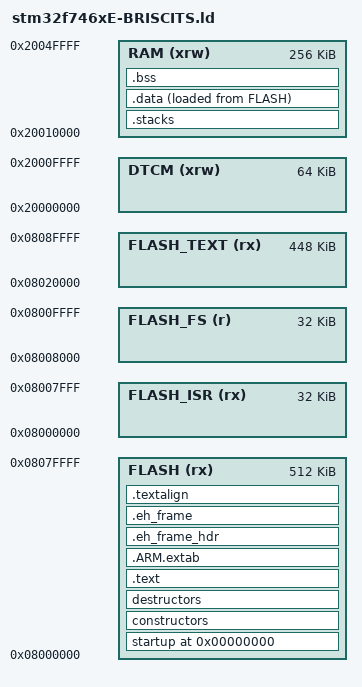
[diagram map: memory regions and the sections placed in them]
/*
    GNU linker script for STM32F746
*/

__main_stack_size__     = 0x0600;
__process_stack_size__  = 0x0600;

/* Specify the memory areas */
MEMORY
{
    FLASH (rx)      : ORIGIN = 0x08000000, LENGTH = 512K
    FLASH_ISR (rx)  : ORIGIN = 0x08000000, LENGTH = 32K     /* sector 0, 32K */
    FLASH_FS (r)    : ORIGIN = 0x08008000, LENGTH = 32K     /* sectors 1 (32K each) */
    FLASH_TEXT (rx) : ORIGIN = 0x08020000, LENGTH = 448K    /* sectors 2-5 2*32Kib 1*128Kib 1*256KiB = 448K */
    DTCM (xrw)      : ORIGIN = 0x20000000, LENGTH = 64K     /* Used for storage cache */
    RAM (xrw)       : ORIGIN = 0x20010000, LENGTH = 256K    /* SRAM1 = 240K, SRAM2 = 16K */
}

__ram_start__           = ORIGIN(RAM);
__ram_size__            = LENGTH(RAM);
__ram_end__             = __ram_start__ + __ram_size__;

SECTIONS
{
    . = 0;
    _text = .;

    startup : ALIGN(16) SUBALIGN(16)
    {
        KEEP(*(.vectors))
    } > FLASH

    constructors : ALIGN(4) SUBALIGN(4)
    {
        PROVIDE(__init_array_start = .);
        KEEP(*(SORT(.init_array.*)))
        KEEP(*(.init_array))
        PROVIDE(__init_array_end = .);
    } > FLASH

    destructors : ALIGN(4) SUBALIGN(4)
    {
        PROVIDE(__fini_array_start = .);
        KEEP(*(.fini_array))
        KEEP(*(SORT(.fini_array.*)))
        PROVIDE(__fini_array_end = .);
    } > FLASH

    .text : ALIGN(16) SUBALIGN(16)
    {
        *(.text.startup.*)
        *(.init)
        *(.text)
        *(.text.*)
        *(.rodata)
        *(.rodata.*)
        *(.glue_7t)
        *(.glue_7)
        *(.gcc*)
    } > FLASH

    .ARM.extab :
    {
        *(.ARM.extab* .gnu.linkonce.armextab.*)
    } > FLASH

/*
    .ARM.exidx : {
        PROVIDE(__exidx_start = .);
        *(.ARM.exidx* .gnu.linkonce.armexidx.*)
        PROVIDE(__exidx_end = .);
     } > FLASH
*/

    .eh_frame_hdr :
    {
        *(.eh_frame_hdr)
    } > FLASH

    .eh_frame : ONLY_IF_RO
    {
        *(.eh_frame)
    } > FLASH

    .textalign : ONLY_IF_RO
    {
        . = ALIGN(8);
    } > FLASH

    _etext = .;
    _textdata = _etext;

    .stacks :
    {
        . = ALIGN(8);
        __main_stack_base__ = .;
        . += __main_stack_size__;
        . = ALIGN(8);
        __main_stack_end__ = .;
        __process_stack_base__ = .;
        __main_thread_stack_base__ = .;
        . += __process_stack_size__;
        . = ALIGN(8);
        __process_stack_end__ = .;
        __main_thread_stack_end__ = .;
    } > RAM

    .data :
    {
        . = ALIGN(4);
        PROVIDE(_data = .);
        *(.data)
        . = ALIGN(4);
        *(.data.*)
        . = ALIGN(4);
        *(.ramtext)
        . = ALIGN(4);
        PROVIDE(_edata = .);
    } > RAM AT > FLASH

    .bss :
    {
        . = ALIGN(4);
        PROVIDE(__bss_start__ = .);
        *(.bss)
        . = ALIGN(4);
        *(.bss.*)
        . = ALIGN(4);
        *(COMMON)
        . = ALIGN(4);
        PROVIDE(__bss_end__ = .);
    } > RAM
}

PROVIDE(end = .);
_end            = .;

__heap_start__   = _end;
__heap_end__    = __ram_end__;




/* produce a link error if there is not this amount of RAM for these sections */
_minimum_stack_size = 2K;
_minimum_heap_size = 16K;

/* Define the stack.  The stack is full descending so begins just above last byte
   of RAM.  Note that EABI requires the stack to be 8-byte aligned for a call. */
_estack = ORIGIN(RAM) + LENGTH(RAM) - _estack_reserve;
_sstack = _estack - 16K; /* tunable */

/* RAM extents for the garbage collector */
_ram_start = ORIGIN(RAM);
_ram_end = ORIGIN(RAM) + LENGTH(RAM);
_heap_start = _ebss; /* heap starts just after statically allocated memory */
_heap_end = _sstack;
